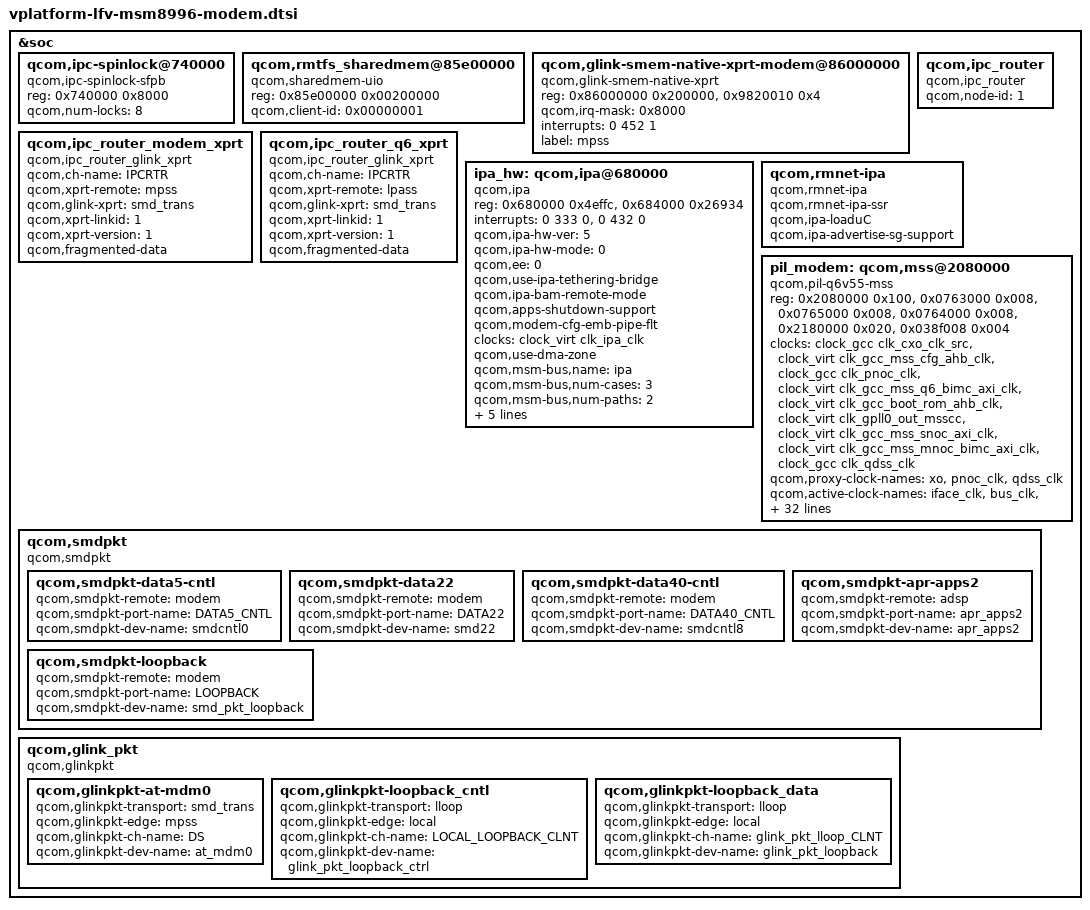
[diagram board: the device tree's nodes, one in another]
/* Copyright (c) 2017-2018, The Linux Foundation. All rights reserved.
 *
 * This program is free software; you can redistribute it and/or modify
 * it under the terms of the GNU General Public License version 2 and
 * only version 2 as published by the Free Software Foundation.
 *
 * This program is distributed in the hope that it will be useful,
 * but WITHOUT ANY WARRANTY; without even the implied warranty of
 * MERCHANTABILITY or FITNESS FOR A PARTICULAR PURPOSE.  See the
 * GNU General Public License for more details.
 */

&soc {
	qcom,ipc-spinlock@740000 {
		compatible = "qcom,ipc-spinlock-sfpb";
		reg = <0x740000 0x8000>;
		qcom,num-locks = <8>;
	};

	qcom,rmtfs_sharedmem@85e00000 {
		compatible = "qcom,sharedmem-uio";
		reg = <0x85e00000 0x00200000>;
		reg-names = "rmtfs";
		qcom,client-id = <0x00000001>;
	};

	qcom,glink-smem-native-xprt-modem@86000000 {
		compatible = "qcom,glink-smem-native-xprt";
		reg = <0x86000000 0x200000>,
			<0x9820010 0x4>;
		reg-names = "smem", "irq-reg-base";
		qcom,irq-mask = <0x8000>;
		interrupts = <0 452 1>;
		label = "mpss";
	};

	qcom,ipc_router {
		compatible = "qcom,ipc_router";
		qcom,node-id = <1>;
	};

	qcom,ipc_router_modem_xprt {
		compatible = "qcom,ipc_router_glink_xprt";
		qcom,ch-name = "IPCRTR";
		qcom,xprt-remote = "mpss";
		qcom,glink-xprt = "smd_trans";
		qcom,xprt-linkid = <1>;
		qcom,xprt-version = <1>;
		qcom,fragmented-data;
	};

	qcom,ipc_router_q6_xprt {
		compatible = "qcom,ipc_router_glink_xprt";
		qcom,ch-name = "IPCRTR";
		qcom,xprt-remote = "lpass";
		qcom,glink-xprt = "smd_trans";
		qcom,xprt-linkid = <1>;
		qcom,xprt-version = <1>;
		qcom,fragmented-data;
	};

	ipa_hw: qcom,ipa@680000 {
		compatible = "qcom,ipa";
		reg = <0x680000 0x4effc>,
			<0x684000 0x26934>;
		reg-names = "ipa-base", "bam-base";
		interrupts = <0 333 0>,
			<0 432 0>;
		interrupt-names = "ipa-irq", "bam-irq";
		qcom,ipa-hw-ver = <5>; /* IPA core version = IPAv2.5 */
		qcom,ipa-hw-mode = <0>;
		qcom,ee = <0>;
		qcom,use-ipa-tethering-bridge;
		qcom,ipa-bam-remote-mode;
		qcom,apps-shutdown-support;
		qcom,modem-cfg-emb-pipe-flt;
		clocks = <&clock_virt clk_ipa_clk>;
		clock-names = "core_clk";
		qcom,use-dma-zone;
		qcom,msm-bus,name = "ipa";
		qcom,msm-bus,num-cases = <3>;
		qcom,msm-bus,num-paths = <2>;
		qcom,msm-bus,vectors-KBps =
		<90 512 0 0>, <90 585 0 0>,         /* No vote */
		<90 512 80000 640000>, <90 585 80000 640000>,    /* SVS */
		<90 512 206000 960000>, <90 585 206000 960000>;    /* PERF */
		qcom,bus-vector-names = "MIN", "SVS", "PERF";
	};

	qcom,rmnet-ipa {
		compatible = "qcom,rmnet-ipa";
		qcom,rmnet-ipa-ssr;
		qcom,ipa-loaduC;
		qcom,ipa-advertise-sg-support;
	};

	pil_modem: qcom,mss@2080000 {
		compatible = "qcom,pil-q6v55-mss";
		reg = <0x2080000 0x100>,
			<0x0763000 0x008>,
			<0x0765000 0x008>,
			<0x0764000 0x008>,
			<0x2180000 0x020>,
			<0x038f008 0x004>;
		reg-names = "qdsp6_base", "halt_q6", "halt_modem",
			"halt_nc", "rmb_base", "restart_reg";

		clocks = <&clock_gcc clk_cxo_clk_src>,
			<&clock_virt clk_gcc_mss_cfg_ahb_clk>,
			<&clock_gcc clk_pnoc_clk>,
			<&clock_virt clk_gcc_mss_q6_bimc_axi_clk>,
			<&clock_virt clk_gcc_boot_rom_ahb_clk>,
			<&clock_virt clk_gpll0_out_msscc>,
			<&clock_virt clk_gcc_mss_snoc_axi_clk>,
			<&clock_virt clk_gcc_mss_mnoc_bimc_axi_clk>,
			<&clock_gcc clk_qdss_clk>;
		clock-names = "xo", "iface_clk", "pnoc_clk", "bus_clk",
				"mem_clk", "gpll0_mss_clk", "snoc_axi_clk",
				"mnoc_axi_clk", "qdss_clk";
		qcom,proxy-clock-names = "xo", "pnoc_clk", "qdss_clk";
		qcom,active-clock-names = "iface_clk", "bus_clk", "mem_clk",
					"gpll0_mss_clk", "snoc_axi_clk",
					"mnoc_axi_clk";

		interrupts = <0 448 1>;
		vdd_cx-supply = <&pm8994_s1_corner>;
		vdd_cx-voltage = <7>;
		vdd_mx-supply = <&pm8994_s2_corner>;
		vdd_mx-uV = <6>;
		vdd_pll-supply = <&pm8994_l12>;
		qcom,vdd_pll = <1800000>;
		qcom,firmware-name = "modem";
		qcom,pil-self-auth;
		qcom,sysmon-id = <0>;
		qcom,ssctl-instance-id = <0x12>;
		qcom,override-acc;
		qcom,ahb-clk-vote;
		qcom,pnoc-clk-vote;
		qcom,qdsp6v56-1-5;
		qcom,mx-spike-wa;
		memory-region = <&modem_mem>;
		qcom,mem-protect-id = <0xF>;

		/* GPIO inputs from mss */
		qcom,gpio-err-fatal = <&smp2pgpio_ssr_smp2p_1_in 0 0>;
		qcom,gpio-err-ready = <&smp2pgpio_ssr_smp2p_1_in 1 0>;
		qcom,gpio-proxy-unvote = <&smp2pgpio_ssr_smp2p_1_in 2 0>;
		qcom,gpio-stop-ack = <&smp2pgpio_ssr_smp2p_1_in 3 0>;
		qcom,gpio-shutdown-ack = <&smp2pgpio_ssr_smp2p_1_in 7 0>;

		/* GPIO output to mss */
		qcom,gpio-force-stop = <&smp2pgpio_ssr_smp2p_1_out 0 0>;
		status = "ok";
	};

	qcom,smdpkt {
		compatible = "qcom,smdpkt";

		qcom,smdpkt-data5-cntl {
			qcom,smdpkt-remote = "modem";
			qcom,smdpkt-port-name = "DATA5_CNTL";
			qcom,smdpkt-dev-name = "smdcntl0";
		};

		qcom,smdpkt-data22 {
			qcom,smdpkt-remote = "modem";
			qcom,smdpkt-port-name = "DATA22";
			qcom,smdpkt-dev-name = "smd22";
		};

		qcom,smdpkt-data40-cntl {
			qcom,smdpkt-remote = "modem";
			qcom,smdpkt-port-name = "DATA40_CNTL";
			qcom,smdpkt-dev-name = "smdcntl8";
		};

		qcom,smdpkt-apr-apps2 {
			qcom,smdpkt-remote = "adsp";
			qcom,smdpkt-port-name = "apr_apps2";
			qcom,smdpkt-dev-name = "apr_apps2";
		};

		qcom,smdpkt-loopback {
			qcom,smdpkt-remote = "modem";
			qcom,smdpkt-port-name = "LOOPBACK";
			qcom,smdpkt-dev-name = "smd_pkt_loopback";
		};
	};

	qcom,glink_pkt {
		compatible = "qcom,glinkpkt";
		qcom,glinkpkt-at-mdm0 {
			qcom,glinkpkt-transport = "smd_trans";
			qcom,glinkpkt-edge = "mpss";
			qcom,glinkpkt-ch-name = "DS";
			qcom,glinkpkt-dev-name = "at_mdm0";
		};

		qcom,glinkpkt-loopback_cntl {
			qcom,glinkpkt-transport = "lloop";
			qcom,glinkpkt-edge = "local";
			qcom,glinkpkt-ch-name = "LOCAL_LOOPBACK_CLNT";
			qcom,glinkpkt-dev-name = "glink_pkt_loopback_ctrl";
		};

		qcom,glinkpkt-loopback_data {
			qcom,glinkpkt-transport = "lloop";
			qcom,glinkpkt-edge = "local";
			qcom,glinkpkt-ch-name = "glink_pkt_lloop_CLNT";
			qcom,glinkpkt-dev-name = "glink_pkt_loopback";
		};
	};
};
